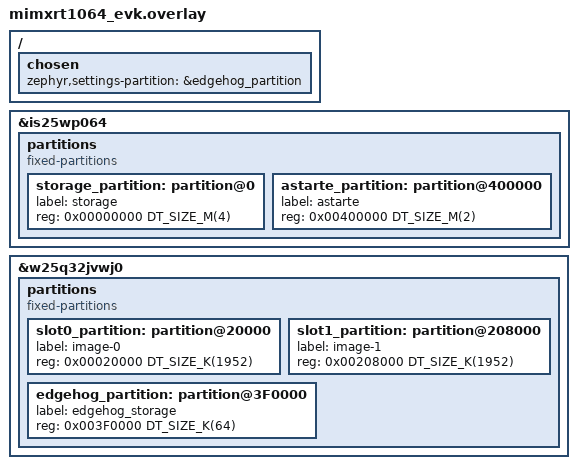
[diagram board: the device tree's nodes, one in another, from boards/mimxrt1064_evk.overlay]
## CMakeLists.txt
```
# (C) Copyright 2024, SECO Mind Srl
#
# SPDX-License-Identifier: Apache-2.0

function(concat_if_exists FILE_PATH STRING_NAME)
    # Check if the file exists
    file(GLOB FILE_TO_ADD ${FILE_PATH})

    # If the file exists, add it to the list
    if(EXISTS ${FILE_TO_ADD})
        set(${STRING_NAME} "${${STRING_NAME}};${FILE_PATH}" PARENT_SCOPE)
    endif()
endfunction()

cmake_minimum_required(VERSION 3.20.0)

# add private configuration for common modules before declaring the zephyr project
concat_if_exists(${CMAKE_CURRENT_LIST_DIR}/private.conf EXTRA_CONF_FILE)

find_package(Zephyr REQUIRED HINTS $ENV{ZEPHYR_BASE})
project(edgehog_app)

FILE(GLOB app_sources ${CMAKE_CURRENT_LIST_DIR}/src/*.c)
if(NOT CONFIG_WIFI)
    LIST(REMOVE_ITEM app_sources ${CMAKE_CURRENT_LIST_DIR}/src/wifi.c)
endif()
if(NOT CONFIG_EDGEHOG_DEVICE_FILE_TRANSFER)
    LIST(REMOVE_ITEM app_sources ${CMAKE_CURRENT_LIST_DIR}/src/file_transfer.c)
endif()

# Verify that this sample is built through sysbuild to ensure MCUboot is
# automatically included and that sample specific MCUboot configurations are
# used when building MCUboot.
test_sysbuild()

target_include_directories(app PRIVATE src/include)
target_sources(app PRIVATE ${app_sources})
```

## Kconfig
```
# (C) Copyright 2024, SECO Mind Srl
#
# SPDX-License-Identifier: Apache-2.0
#
# This file is the application Kconfig entry point. All application Kconfig
# options can be defined here or included via other application Kconfig files.
# You can browse these options using the west targets menuconfig (terminal) or
# guiconfig (GUI).

menu "Zephyr"
source "Kconfig.zephyr"
endmenu

rsource "../../Kconfig"

menu "Sample application"

config WIFI_SSID
    string "WiFi SSID"
	depends on WIFI
    default ""
	help
	  WiFi access point SSID.

config WIFI_PASSWORD
    string "WiFi password"
	depends on WIFI
    default ""
    help
        WiFi access point password.

config ASTARTE_DEVICE_ID
	string "Astarte device ID"
    default ""
	help
	  Device ID to be used to connect to Astarte.

config ASTARTE_CREDENTIAL_SECRET
    string "Astarte credential secret"
    default ""
    help
        The credential secret to be used to connect to Astarte.

config SAMPLE_DURATION_SECONDS
    int "Sample maximum duration (s)"
    default 240
    help
        Use this setting to change for how long the sample will run.
        The default is four minutes.

config EDGEHOG_DEVICE_THREAD_STACK_SIZE
    int "Edgehog device thread stack size (Bytes)"
    default 16384
    help
        Use this setting to change the size of the stack for the thread running the Astarte device.

config EDGEHOG_DEVICE_THREAD_PRIORITY
    int "Edgehog device thread priority"
    default 0
    help
        Use this setting to change the priority of the Astarte device thread.

config ZBUS_THREAD_STACK_SIZE
    int "Zbus thread stack size (Bytes)"
    default 16384
    help
        Use this setting to change the size of the stack for the thread running the Zbus subscriber.

config ZBUS_THREAD_PRIORITY
    int "Zbus thread priority"
    default 0
    help
        Use this setting to change the priority of the Zbus subscriber thread.

endmenu

module = APP
module-str = APP
source "subsys/logging/Kconfig.template.log_config"
```

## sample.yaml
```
# (C) Copyright 2024, SECO Mind Srl
#
# SPDX-License-Identifier: Apache-2.0
# This file is provided so that the application can be compiled using Twister,
# the Zephyr testing tool. In this file, multiple combinations can be specified,
# so that you can easily test all of them locally or in CI.
sample:
  description: Edgehog application sample
  name: edgehog-sample
tests:
  sample.default:
    build_only: true
    sysbuild: true
    integration_platforms:
      - mimxrt1064_evk
      - mimxrt1060_evk@B/mimxrt1062/qspi
      - stm32h573i_dk
      - esp_wrover_kit/esp32/procpu
  sample.wifi:
    build_only: true
    sysbuild: true
    extra_args: EXTRA_CONF_FILE="prj-wifi.conf"
    integration_platforms:
      - frdm_rw612
  sample.msv:
    build_only: true
    sysbuild: true
    extra_args: CONF_FILE="prj-zephyr-msv.conf"
    integration_platforms:
      - frdm_rw612
      - stm32h573i_dk
```

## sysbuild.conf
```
# (C) Copyright 2024, SECO Mind Srl
#
# SPDX-License-Identifier: Apache-2.0

SB_CONFIG_BOOTLOADER_MCUBOOT=y
SB_CONFIG_MCUBOOT_MODE_OVERWRITE_ONLY=y
```

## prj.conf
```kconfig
# (C) Copyright 2024, SECO Mind Srl
#
# SPDX-License-Identifier: Apache-2.0
#
# This is a Kconfig fragment which can be used to enable debug-related options
# in the application. See the README for more details.

# Astarte device SDK
CONFIG_ASTARTE_DEVICE_SDK=y
CONFIG_ASTARTE_DEVICE_SDK_HOSTNAME="."
# The two certificate tags are the same as the root CA is the same for Astarte API and MQTT broker.
CONFIG_ASTARTE_DEVICE_SDK_HTTPS_CA_CERT_TAG=1
CONFIG_ASTARTE_DEVICE_SDK_MQTTS_CA_CERT_TAG=1
CONFIG_ASTARTE_DEVICE_SDK_CLIENT_CERT_TAG=2
CONFIG_ASTARTE_DEVICE_SDK_PAIRING_JWT=""
CONFIG_ASTARTE_DEVICE_SDK_REALM_NAME="."

# Edgehog device
CONFIG_EDGEHOG_DEVICE=y
CONFIG_EDGEHOG_DEVICE_OTA_HTTPS_CA_CERT_TAG=3
CONFIG_EDGEHOG_DEVICE_ZBUS_OTA_EVENT=y
# System info interface data
CONFIG_EDGEHOG_DEVICE_PART_NUMBER=""
CONFIG_EDGEHOG_DEVICE_SERIAL_NUMBER=""

# Sample configuration
CONFIG_ASTARTE_CREDENTIAL_SECRET="."
CONFIG_ASTARTE_DEVICE_ID="......................"

# Enable logging with floating point support
CONFIG_LOG=y
CONFIG_REQUIRES_FLOAT_PRINTF=y
CONFIG_CBPRINTF_FP_SUPPORT=y

# Increase minimum heap size.
CONFIG_HEAP_MEM_POOL_SIZE=16384

# Increased stack size
CONFIG_MAIN_STACK_SIZE=8192

# Use custom heap
CONFIG_ASTARTE_DEVICE_SDK_ENABLE_HEAP=y

# Enable base64 encoding and decoding
CONFIG_BASE64=y

# Enable system hashmaps
CONFIG_SYS_HASH_MAP=y

# Enable JSON library
CONFIG_JSON_LIBRARY=y

# Enable entropy generator
CONFIG_ENTROPY_GENERATOR=y

# DNS resolver
CONFIG_DNS_RESOLVER=y
CONFIG_DNS_SERVER_IP_ADDRESSES=y
CONFIG_DNS_SERVER1="8.8.8.8" # Google DNS

# Base MbedTLS & heap configuration
CONFIG_MBEDTLS=y
CONFIG_MBEDTLS_BUILTIN=y
CONFIG_MBEDTLS_ENABLE_HEAP=y
CONFIG_MBEDTLS_HEAP_SIZE=95000

# Enable PSA Crypto Backend
CONFIG_PSA_CRYPTO=y
CONFIG_PSA_CRYPTO_ENABLE_ALL=y
CONFIG_MBEDTLS_PSA_CRYPTO_C=y

# TLS & X.509
CONFIG_MBEDTLS_SSL_MAX_CONTENT_LEN=8192
CONFIG_MBEDTLS_PEM_PARSE_C=y
CONFIG_MBEDTLS_PEM_WRITE_C=y
CONFIG_MBEDTLS_BASE64_C=y
CONFIG_MBEDTLS_PK_WRITE_C=y
CONFIG_MBEDTLS_SSL_PROTO_TLS1_2=y
CONFIG_MBEDTLS_SSL_SERVER_NAME_INDICATION=y
CONFIG_MBEDTLS_X509_USE_C=y
CONFIG_MBEDTLS_X509_CRT_PARSE_C=y
CONFIG_MBEDTLS_X509_CRL_PARSE_C=y
CONFIG_MBEDTLS_X509_CSR_PARSE_C=y
CONFIG_MBEDTLS_X509_CSR_WRITE_C=y
CONFIG_MBEDTLS_PKCS5_C=y
CONFIG_MBEDTLS_KEY_EXCHANGE_ECDHE_ECDSA_ENABLED=y
CONFIG_MBEDTLS_KEY_EXCHANGE_ECDHE_RSA_ENABLED=y

# Enable networking
CONFIG_NETWORKING=y

# Sockets
CONFIG_NET_SOCKETS=y
CONFIG_NET_SOCKETS_SOCKOPT_TLS=y

# Use DHCP for IPv4 and IPv6
CONFIG_NET_DHCPV4=y
CONFIG_NET_DHCPV6=y

# Generic networking options
CONFIG_NET_TX_STACK_SIZE=4096
CONFIG_NET_RX_STACK_SIZE=4096
CONFIG_NET_PKT_RX_COUNT=20
CONFIG_NET_PKT_TX_COUNT=20
CONFIG_NET_BUF_RX_COUNT=40
CONFIG_NET_BUF_TX_COUNT=40
CONFIG_NET_MAX_CONTEXTS=20
CONFIG_NET_MAX_CONN=6
CONFIG_NET_MGMT=y
CONFIG_NET_MGMT_EVENT=y
CONFIG_NET_IPV4=y
CONFIG_NET_IPV6=y
CONFIG_NET_TCP=y

# Enable HTTP client
CONFIG_HTTP_CLIENT=y

# MQTT options
CONFIG_MQTT_LIB=y
CONFIG_MQTT_LIB_TLS=y
CONFIG_MQTT_KEEPALIVE=60

# Enable flash
CONFIG_FLASH=y
CONFIG_FLASH_MAP=y
CONFIG_FLASH_PAGE_LAYOUT=y

# Enable NVS
CONFIG_NVS=y
CONFIG_NVS_LOG_LEVEL_WRN=y

# Enable storage
CONFIG_ZMS=y
CONFIG_ZMS_LOG_LEVEL_WRN=y

# Enable hash functions
CONFIG_SYS_HASH_FUNC32=y
CONFIG_SYS_HASH_FUNC32_MURMUR3=y


# Configure the name of the binary
# This will also be used to identify the edgehog image
CONFIG_KERNEL_BIN_NAME="sample-edgehog-app"

# Edgehog depends on
CONFIG_IMG_MANAGER=y
CONFIG_STREAM_FLASH=y
CONFIG_REBOOT=y

CONFIG_DNS_RESOLVER_AI_MAX_ENTRIES=4
CONFIG_NET_SOCKETS_TLS_MAX_CONTEXTS=4
CONFIG_TLS_MAX_CREDENTIALS_NUMBER=8

CONFIG_THREAD_MONITOR=y
CONFIG_INIT_STACKS=y
CONFIG_THREAD_STACK_INFO=y

CONFIG_ZVFS_OPEN_MAX=26

CONFIG_SNTP=y
CONFIG_NET_CONFIG_CLOCK_SNTP_INIT=y
CONFIG_NET_CONFIG_SNTP_INIT_SERVER="0.pool.ntp.org"
CONFIG_NET_CONFIG_SNTP_INIT_TIMEOUT=3000

# Enable the settings
CONFIG_SETTINGS=y

# Activate Zbus
CONFIG_ZBUS=y

# Activate thread naming
CONFIG_THREAD_NAME=y

# Enable events
CONFIG_EVENTS=y

# Enable littlefs
CONFIG_FILE_SYSTEM=y
CONFIG_FILE_SYSTEM_LITTLEFS=y

# Increase the system workqueue stack
CONFIG_SYSTEM_WORKQUEUE_STACK_SIZE=4096

# Enable UUID
CONFIG_UUID=y
CONFIG_UUID_V4=y
CONFIG_UUID_V5=y
CONFIG_UUID_BASE64=y

# Enable LZ4 compression
CONFIG_LZ4=y
CONFIG_LZ4_FRAME_SUPPORT=y

# Enable scoped cleanup helpers
CONFIG_SCOPE_CLEANUP_HELPERS=y
```

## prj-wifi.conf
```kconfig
# (C) Copyright 2025, SECO Mind Srl
#
# SPDX-License-Identifier: Apache-2.0
#
# This is a Kconfig fragment which can be used to enable debug-related options
# in the application. See the README for more details.

CONFIG_WIFI=y
CONFIG_ETH_DRIVER=n

CONFIG_NET_IPV6=n
CONFIG_NET_DHCPV6=n

# Increased stack size
CONFIG_MAIN_STACK_SIZE=65536
```

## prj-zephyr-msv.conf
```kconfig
# (C) Copyright 2026, SECO Mind Srl
#
# SPDX-License-Identifier: Apache-2.0
#
# This is a Kconfig fragment which can be used to enable debug-related options
# in the application. See the README for more details.

# Astarte device SDK
CONFIG_ASTARTE_DEVICE_SDK=y
CONFIG_ASTARTE_DEVICE_SDK_HOSTNAME="."
# The two certificate tags are the same as the root CA is the same for Astarte API and MQTT broker.
CONFIG_ASTARTE_DEVICE_SDK_HTTPS_CA_CERT_TAG=1
CONFIG_ASTARTE_DEVICE_SDK_MQTTS_CA_CERT_TAG=1
CONFIG_ASTARTE_DEVICE_SDK_CLIENT_CERT_TAG=2
CONFIG_ASTARTE_DEVICE_SDK_PAIRING_JWT=""
CONFIG_ASTARTE_DEVICE_SDK_REALM_NAME="."
# Edgehog device
CONFIG_EDGEHOG_DEVICE=y
CONFIG_EDGEHOG_DEVICE_OTA_HTTPS_CA_CERT_TAG=3
CONFIG_EDGEHOG_DEVICE_ZBUS_OTA_EVENT=y
# System info interface data
CONFIG_EDGEHOG_DEVICE_PART_NUMBER=""
CONFIG_EDGEHOG_DEVICE_SERIAL_NUMBER=""

# Sample configuration
CONFIG_ASTARTE_CREDENTIAL_SECRET="."
CONFIG_ASTARTE_DEVICE_ID="......................"

# Enable logging with floating point support
CONFIG_LOG=y
CONFIG_REQUIRES_FLOAT_PRINTF=y
CONFIG_CBPRINTF_FP_SUPPORT=y

# Increase minimum heap size.
CONFIG_HEAP_MEM_POOL_SIZE=16384

# Increased stack size
CONFIG_MAIN_STACK_SIZE=8192

# Use custom heap
CONFIG_ASTARTE_DEVICE_SDK_ENABLE_HEAP=y

# Enable base64 encoding and decoding
CONFIG_BASE64=y

# Enable system hashmaps
CONFIG_SYS_HASH_MAP=y

# Enable JSON library
CONFIG_JSON_LIBRARY=y

# Enable entropy generator
CONFIG_ENTROPY_GENERATOR=y

# DNS resolver
CONFIG_DNS_RESOLVER=y
CONFIG_DNS_SERVER_IP_ADDRESSES=y
CONFIG_DNS_SERVER1="8.8.8.8" # Google DNS

# Base MbedTLS & heap configuration
CONFIG_MBEDTLS=y
CONFIG_MBEDTLS_BUILTIN=y
CONFIG_MBEDTLS_ENABLE_HEAP=y
CONFIG_MBEDTLS_HEAP_SIZE=55000

# Enable PSA Crypto Backend
CONFIG_PSA_CRYPTO=y
CONFIG_PSA_CRYPTO_ENABLE_ALL=y
CONFIG_MBEDTLS_USE_PSA_CRYPTO=y
CONFIG_MBEDTLS_PSA_CRYPTO_C=y

# TLS & X.509
CONFIG_MBEDTLS_SSL_MAX_CONTENT_LEN=8192
CONFIG_MBEDTLS_PEM_CERTIFICATE_FORMAT=y
CONFIG_MBEDTLS_PK_WRITE_C=y
CONFIG_MBEDTLS_SSL_PROTO_TLS1_2=y
CONFIG_MBEDTLS_SERVER_NAME_INDICATION=y
CONFIG_MBEDTLS_X509_CRL_PARSE_C=y
CONFIG_MBEDTLS_X509_CSR_PARSE_C=y
CONFIG_MBEDTLS_X509_CSR_WRITE_C=y
CONFIG_MBEDTLS_PKCS5_C=y
CONFIG_MBEDTLS_GENPRIME_ENABLED=y
CONFIG_MBEDTLS_KEY_EXCHANGE_ECDHE_ECDSA_ENABLED=y
CONFIG_MBEDTLS_KEY_EXCHANGE_ECDHE_RSA_ENABLED=y
CONFIG_MBEDTLS_ECDH_C=y
CONFIG_MBEDTLS_ECDSA_C=y
CONFIG_MBEDTLS_ECP_C=y
CONFIG_MBEDTLS_ECP_DP_SECP256R1_ENABLED=y

# Enable networking
CONFIG_NETWORKING=y

# Sockets
CONFIG_NET_SOCKETS=y
CONFIG_NET_SOCKETS_SOCKOPT_TLS=y

# Use DHCP for IPv4 and IPv6
CONFIG_NET_DHCPV4=y
CONFIG_NET_DHCPV6=y

# Generic networking options
CONFIG_NET_TX_STACK_SIZE=4096
CONFIG_NET_RX_STACK_SIZE=4096
CONFIG_NET_PKT_RX_COUNT=20
CONFIG_NET_PKT_TX_COUNT=20
CONFIG_NET_BUF_RX_COUNT=40
CONFIG_NET_BUF_TX_COUNT=40
CONFIG_NET_MAX_CONTEXTS=20
CONFIG_NET_MAX_CONN=6
CONFIG_NET_MGMT=y
CONFIG_NET_MGMT_EVENT=y
CONFIG_NET_IPV4=y
CONFIG_NET_IPV6=y
CONFIG_NET_TCP=y

# Enable HTTP client
CONFIG_HTTP_CLIENT=y

# MQTT options
CONFIG_MQTT_LIB=y
CONFIG_MQTT_LIB_TLS=y
CONFIG_MQTT_KEEPALIVE=60

# Enable flash
CONFIG_FLASH=y
CONFIG_FLASH_MAP=y
CONFIG_FLASH_PAGE_LAYOUT=y

# Enable NVS
CONFIG_NVS=y
CONFIG_NVS_LOG_LEVEL_WRN=y

# Enable storage
CONFIG_ZMS=y
CONFIG_ZMS_LOG_LEVEL_WRN=y

# Enable hash functions
CONFIG_SYS_HASH_FUNC32=y
CONFIG_SYS_HASH_FUNC32_MURMUR3=y

# Configure the name of the binary
# This will also be used to identify the edgehog image
CONFIG_KERNEL_BIN_NAME="sample-edgehog-app"

# Edgehog depends on
CONFIG_IMG_MANAGER=y
CONFIG_STREAM_FLASH=y
CONFIG_REBOOT=y

CONFIG_DNS_RESOLVER_AI_MAX_ENTRIES=4
CONFIG_NET_SOCKETS_TLS_MAX_CONTEXTS=4
CONFIG_TLS_MAX_CREDENTIALS_NUMBER=8

CONFIG_THREAD_MONITOR=y
CONFIG_INIT_STACKS=y
CONFIG_THREAD_STACK_INFO=y

CONFIG_ZVFS_OPEN_MAX=26

CONFIG_SNTP=y
CONFIG_NET_CONFIG_CLOCK_SNTP_INIT=y
CONFIG_NET_CONFIG_SNTP_INIT_SERVER="0.pool.ntp.org"
CONFIG_NET_CONFIG_SNTP_INIT_TIMEOUT=3000

# Enable the settings
CONFIG_SETTINGS=y

# Activate Zbus
CONFIG_ZBUS=y

# Set thread names
CONFIG_THREAD_NAME=y

# Enable UUID
CONFIG_UUID=y
CONFIG_UUID_V4=y
CONFIG_UUID_V5=y
CONFIG_UUID_BASE64=y

# Enable events
CONFIG_EVENTS=y
```

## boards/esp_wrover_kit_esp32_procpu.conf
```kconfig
# (C) Copyright 2026, SECO Mind Srl
#
# SPDX-License-Identifier: Apache-2.0

# Wi-Fi Configuration
CONFIG_WIFI=y
CONFIG_WIFI_ESP32=y

# increase network buffer size to avoid first connection attempt error
CONFIG_NET_BUF_TX_COUNT=64
CONFIG_NET_BUF_RX_COUNT=64

# ESP32 hardware random number generator is required for secure TLS
CONFIG_ENTROPY_ESP32_RNG=y

# Enable WROVER PSRAM
CONFIG_ESP_SPIRAM=y
# 2MB instead of deafult 256KB
CONFIG_ESP_SPIRAM_HEAP_SIZE=2097152

# Optimizations to save internal RAM used by the Wi-Fi driver
CONFIG_ESP_WIFI_HEAP_SPIRAM=y
CONFIG_ESP32_WIFI_NET_ALLOC_SPIRAM=y
CONFIG_ESP32_WIFI_RX_IRAM_OPT=n
CONFIG_ESP32_WIFI_IRAM_OPT=n

# Move MbedTLS heap to external RAM
CONFIG_MBEDTLS_HEAP_CUSTOM_SECTION=y
```

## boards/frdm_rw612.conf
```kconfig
# (C) Copyright 2025, SECO Mind Srl
#
# SPDX-License-Identifier: Apache-2.0

# Enable the WiFi
CONFIG_WIFI_NXP=y

# Use a large log buffer size
CONFIG_LOG_BUFFER_SIZE=32768

# Enable the file transfer
CONFIG_EDGEHOG_DEVICE_FILE_TRANSFER=y
CONFIG_EDGEHOG_DEVICE_FILE_TRANSFER_HTTPS_CA_CERT_TAG=4
CONFIG_EDGEHOG_DEVICE_FILE_TRANSFER_COMPRESSION=y
CONFIG_EDGEHOG_DEVICE_FILE_TRANSFER_TAR=y
```

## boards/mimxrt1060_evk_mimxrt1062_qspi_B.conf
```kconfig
# (C) Copyright 2024, SECO Mind Srl
#
# SPDX-License-Identifier: Apache-2.0

# Ethernet settings
CONFIG_NET_L2_ETHERNET=y
CONFIG_NET_L2_ETHERNET_MGMT=y

CONFIG_LOG_MODE_DEFERRED=y
CONFIG_LOG_BUFFER_SIZE=32768
```

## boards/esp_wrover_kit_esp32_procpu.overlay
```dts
/*
 * (C) Copyright 2026, SECO Mind Srl
 *
 * SPDX-License-Identifier: Apache-2.0
 */

/delete-node/ &storage_partition;

&flash0 {
	partitions {
		compatible = "fixed-partitions";
		#address-cells = <1>;
		#size-cells = <1>;

        storage_partition: partition@3b0000 {
			label = "storage";
			reg = <0x3B0000 DT_SIZE_K(64)>;
		};

		astarte_partition: partition@3c0000 {
			label = "astarte";
			reg = <0x003C0000 DT_SIZE_K(64)>;
		};

		edgehog_partition: partition@3d0000 {
			label = "edgehog";
			reg = <0x003D0000 DT_SIZE_K(64)>;
		};
	};
};
```

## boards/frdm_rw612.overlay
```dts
/*
 * (C) Copyright 2025, SECO Mind Srl
 *
 * SPDX-License-Identifier: Apache-2.0
 */

/delete-node/ &storage_partition;

/ {
    fstab {
        compatible = "zephyr,fstab";
        lfs1: lfs1 {
            compatible = "zephyr,fstab,littlefs";
            mount-point = "/lfs1";
            partition = <&file_transfer_partition>;
            automount;
            read-size = <16>;
            prog-size = <16>;
            cache-size = <64>;
            lookahead-size = <32>;
            block-cycles = <512>;
        };
    };
};

&w25q512jvfiq {
    partitions {
        compatible = "fixed-partitions";
        #address-cells = <1>;
        #size-cells = <1>;

        storage_partition: partition@620000 {
            label = "storage";
            reg = <0x00620000 (DT_SIZE_M(55) - DT_SIZE_K(128))>;
        };

        astarte_partition: partition@3D00000 {
            label = "astarte";
            reg = <0x03D00000 DT_SIZE_M(1)>;
        };

        edgehog_partition: partition@3E00000 {
            label = "edgehog";
            reg = <0x03E00000 DT_SIZE_M(1)>;
        };

        file_transfer_partition: partition@3F00000 {
            label = "file_transfer";
            reg = <0x03F00000 DT_SIZE_M(1)>;
        };
    };
};

/ {
    chosen {
        zephyr,settings-partition = &edgehog_partition;
    };
};
```

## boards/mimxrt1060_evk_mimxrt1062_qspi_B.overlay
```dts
/*
 * (C) Copyright 2024, SECO Mind Srl
 *
 * SPDX-License-Identifier: Apache-2.0
 */

/delete-node/ &storage_partition;

/delete-node/ &slot0_partition;
/delete-node/ &slot1_partition;

&is25wp064 {
    partitions {
        compatible = "fixed-partitions";
        #address-cells = <1>;
        #size-cells = <1>;

        slot0_partition: partition@20000 {
            label = "image-0";
            reg = <0x00020000 DT_SIZE_K(1952)>;
        };

        slot1_partition: partition@208000 {
            label = "image-1";
            reg = <0x00208000 DT_SIZE_K(1952)>;
        };

        storage_partition: partition@3F0000 {
            label = "storage";
            reg = <0x003F0000 DT_SIZE_M(1)>;
        };

        astarte_partition: partition@4F0000 {
            label = "astarte";
            reg = <0x004F0000 DT_SIZE_M(1)>;
        };

        edgehog_partition: partition@5F0000 {
            label = "edgehog_storage";
            reg = <0x005F0000 DT_SIZE_K(64)>;
        };
    };
};

/ {
    chosen {
        zephyr,settings-partition = &edgehog_partition;
    };
};
```

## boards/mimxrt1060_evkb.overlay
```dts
/*
 * (C) Copyright 2024, SECO Mind Srl
 *
 * SPDX-License-Identifier: Apache-2.0
 */

/delete-node/ &storage_partition;

/delete-node/ &slot0_partition;
/delete-node/ &slot1_partition;

&is25wp064 {
	partitions {
		compatible = "fixed-partitions";
		#address-cells = <1>;
		#size-cells = <1>;

		slot0_partition: partition@20000 {
			label = "image-0";
			reg = <0x00020000 DT_SIZE_K(1952)>;
		};

		slot1_partition: partition@208000 {
			label = "image-1";
			reg = <0x00208000 DT_SIZE_K(1952)>;
		};

		storage_partition: partition@3F0000 {
			label = "storage";
			reg = <0x003F0000 DT_SIZE_M(1)>;
		};

		astarte_partition: partition@4F0000 {
			label = "astarte";
			reg = <0x004F0000 DT_SIZE_M(1)>;
		};

		edgehog_partition: partition@5F0000 {
			label = "edgehog_storage";
			reg = <0x005F0000 DT_SIZE_K(64)>;
		};
	};
};

/ {
	chosen {
		zephyr,settings-partition = &edgehog_partition;
	};
};
```

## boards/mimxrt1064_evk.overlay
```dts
/*
 * (C) Copyright 2024, SECO Mind Srl
 *
 * SPDX-License-Identifier: Apache-2.0
 */

/delete-node/ &storage_partition;

/delete-node/ &slot0_partition;
/delete-node/ &slot1_partition;

&is25wp064 {
    partitions {
        compatible = "fixed-partitions";
        #address-cells = <1>;
        #size-cells = <1>;

        storage_partition: partition@0 {
            label = "storage";
            reg = <0x00000000 DT_SIZE_M(4)>;
        };

        astarte_partition: partition@400000 {
            label = "astarte";
            reg = <0x00400000 DT_SIZE_M(2)>;
        };
    };
};


&w25q32jvwj0 {
    partitions {
        compatible = "fixed-partitions";
        #address-cells = <1>;
        #size-cells = <1>;

        slot0_partition: partition@20000 {
            label = "image-0";
            reg = <0x00020000 DT_SIZE_K(1952)>;
        };

        slot1_partition: partition@208000 {
            label = "image-1";
            reg = <0x00208000 DT_SIZE_K(1952)>;
        };

        /*
        * Reserve the final 64 KiB for edgehog partition
        */
        edgehog_partition: partition@3F0000 {
            label = "edgehog_storage";
            reg = <0x003F0000 DT_SIZE_K(64)>;
        };
    };
};

/ {
    chosen {
        zephyr,settings-partition = &edgehog_partition;
    };
};
```

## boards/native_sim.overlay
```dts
/*
 * (C) Copyright 2024, SECO Mind Srl
 *
 * SPDX-License-Identifier: Apache-2.0
 */

&flash0 {
    partitions {
        compatible = "fixed-partitions";
        #address-cells = <1>;
        #size-cells = <1>;

        astarte_partition: partition@100000 {
            label = "astarte";
            reg = <0x00100000 DT_SIZE_K(128)>;
        };
        edgehog_partition: partition@120000 {
            label = "edgehog";
            reg = <0x00120000 DT_SIZE_K(128)>;
        };
    };
};

/ {
    chosen {
        zephyr,settings-partition = &edgehog_partition;
    };
};
```

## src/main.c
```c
/*
 * (C) Copyright 2024, SECO Mind Srl
 *
 * SPDX-License-Identifier: Apache-2.0
 */

#include <time.h>

#include <zephyr/kernel.h>
#include <zephyr/net/net_mgmt.h>
#include <zephyr/net/sntp.h>
#include <zephyr/sys/clock.h>

#include <zephyr/logging/log.h>
LOG_MODULE_REGISTER(edgehog_app, CONFIG_APP_LOG_LEVEL); // NOLINT

#if (!defined(CONFIG_ASTARTE_DEVICE_SDK_DEVELOP_USE_NON_TLS_HTTP)                                  \
    || !defined(CONFIG_ASTARTE_DEVICE_SDK_DEVELOP_USE_NON_TLS_MQTT))
#include "ca_certificates.h"
#include <zephyr/net/tls_credentials.h>
#endif

#include <astarte_device_sdk/device.h>

#ifdef CONFIG_EDGEHOG_DEVICE_ZBUS_OTA_EVENT
#include <edgehog_device/ota_event.h>
#endif
#include <edgehog_device/device.h>
#include <edgehog_device/telemetry.h>

#ifdef CONFIG_WIFI
#include "wifi.h"
#else
#include "eth.h"
#endif

#ifdef CONFIG_EDGEHOG_DEVICE_FILE_TRANSFER
#include "file_transfer.h"
#endif

/************************************************
 *             Constants and defines            *
 ***********************************************/

#define MAIN_THREAD_PERIOD_MS 500
#define EDGEHOG_DEVICE_PERIOD_MS 500
#ifdef CONFIG_EDGEHOG_DEVICE_ZBUS_OTA_EVENT
#define ZBUS_PERIOD_MS 500
#endif

#define HTTP_TIMEOUT_MS (3 * MSEC_PER_SEC)
#define MQTT_FIRST_POLL_TIMEOUT_MS (3 * MSEC_PER_SEC)
#define MQTT_POLL_TIMEOUT_MS 200

#define TELEMETRY_SYSTEM_STATUS_PERIOD_S 5
#define TELEMETRY_WIFI_SCAN_PERIOD_S 30

// NOLINTBEGIN(cppcoreguidelines-avoid-non-const-global-variables)
enum device_tread_flags
{
    DEVICE_THREADS_FLAGS_TERMINATION = 1U,
    DEVICE_THREADS_FLAGS_CONNECT_ASTARTE,
    DEVICE_THREADS_FLAGS_START_EDGEHOG,
};
static atomic_t device_threads_flags;

K_THREAD_STACK_DEFINE(edgehog_device_thread_stack_area, CONFIG_EDGEHOG_DEVICE_THREAD_STACK_SIZE);
static struct k_thread edgehog_device_thread_data;

static edgehog_device_handle_t edgehog_device;

#ifdef CONFIG_EDGEHOG_DEVICE_ZBUS_OTA_EVENT
K_THREAD_STACK_DEFINE(zbus_thread_stack_area, CONFIG_ZBUS_THREAD_STACK_SIZE);
static struct k_thread zbus_thread_data;
// Define a zbus subscriber and add it as an observer to the Edgehog OTA channel
#define EDGEHOG_OTA_SUBSCRIBER_NOTIFICATION_QUEUE_SIZE 5
#define EDGEHOG_OTA_OBSERVER_NOTIFY_PRIORITY 5
ZBUS_SUBSCRIBER_DEFINE(edgehog_ota_subscriber, EDGEHOG_OTA_SUBSCRIBER_NOTIFICATION_QUEUE_SIZE);
ZBUS_CHAN_ADD_OBS(edgehog_ota_chan, edgehog_ota_subscriber, EDGEHOG_OTA_OBSERVER_NOTIFY_PRIORITY);
#endif
// NOLINTEND(cppcoreguidelines-avoid-non-const-global-variables)

/************************************************
 *         Static functions declarations        *
 ***********************************************/

/**
 * @brief Initialize System Time
 */
static void system_time_init(void);
/**
 * @brief Entry point for the Edgehog device thread.
 *
 * @param arg1 Unused argument.
 * @param arg2 Unused argument.
 * @param arg3 Unused argument.
 */
static void edgehog_device_thread_entry_point(void *arg1, void *arg2, void *arg3);
#ifdef CONFIG_EDGEHOG_DEVICE_ZBUS_OTA_EVENT
/**
 * @brief Entry point for the Zbus reception thread.
 *
 * @param arg1 Unused argument.
 * @param arg2 Unused argument.
 * @param arg3 Unused argument.
 */
static void zbus_thread_entry_point(void *arg1, void *arg2, void *arg3);
/**
 * @brief Listen on the Edgehog zbus channel for events.
 *
 * @param timeout The timeout used for listening. In case of a received notification this timeout
 * is also used for reading the message.
 */
static void edgehog_listen_zbus_channel(k_timeout_t timeout);
#endif

/************************************************
 *         Global functions definition          *
 ***********************************************/

// NOLINTNEXTLINE(hicpp-function-size)
int main(void)
{
    LOG_INF("Edgehog device sample"); // NOLINT
    LOG_INF("Board: %s", CONFIG_BOARD); // NOLINT

#ifdef CONFIG_WIFI
    LOG_INF("Initializing WiFi driver."); // NOLINT
    app_wifi_init();
    k_sleep(K_SECONDS(5));
    const char *ssid = CONFIG_WIFI_SSID;
    enum wifi_security_type sec = WIFI_SECURITY_TYPE_PSK;
    const char *psk = CONFIG_WIFI_PASSWORD;
    if (app_wifi_connect(ssid, sec, psk) != 0) {
        LOG_ERR("Connectivity intialization failed!"); // NOLINT
        return -1;
    }
#else
    LOG_INF("Initializing Ethernet driver."); // NOLINT
    if (eth_connect() != 0) {
        LOG_ERR("Connectivity intialization failed!"); // NOLINT
        return -1;
    }
#endif

    // Add TLS certificate for Astarte if required
#if (!defined(CONFIG_ASTARTE_DEVICE_SDK_DEVELOP_USE_NON_TLS_HTTP)                                  \
    || !defined(CONFIG_ASTARTE_DEVICE_SDK_DEVELOP_USE_NON_TLS_MQTT))
    tls_credential_add(CONFIG_ASTARTE_DEVICE_SDK_HTTPS_CA_CERT_TAG, TLS_CREDENTIAL_CA_CERTIFICATE,
        astarte_ca_certificate_root, sizeof(astarte_ca_certificate_root));
#endif

    // Add TLS certificate for Edgehog if required
#ifndef CONFIG_EDGEHOG_DEVICE_DEVELOP_USE_NON_TLS_HTTP
    tls_credential_add(CONFIG_EDGEHOG_DEVICE_OTA_HTTPS_CA_CERT_TAG, TLS_CREDENTIAL_CA_CERTIFICATE,
        edgehog_ota_ca_certificate_root, sizeof(edgehog_ota_ca_certificate_root));
#ifdef CONFIG_EDGEHOG_DEVICE_FILE_TRANSFER_HTTPS_CA_CERT_TAG
    tls_credential_add(CONFIG_EDGEHOG_DEVICE_FILE_TRANSFER_HTTPS_CA_CERT_TAG,
        TLS_CREDENTIAL_CA_CERTIFICATE, edgehog_ft_ca_certificate_root,
        sizeof(edgehog_ft_ca_certificate_root));
#endif
#endif

    // Initialize system time
    system_time_init();

    // Spawn a new thread for the Edgehog device
    k_tid_t thread_id = k_thread_create(&edgehog_device_thread_data,
        edgehog_device_thread_stack_area, K_THREAD_STACK_SIZEOF(edgehog_device_thread_stack_area),
        edgehog_device_thread_entry_point, NULL, NULL, NULL, CONFIG_EDGEHOG_DEVICE_THREAD_PRIORITY,
        0, K_NO_WAIT);

#ifdef CONFIG_THREAD_NAME
    int ret = k_thread_name_set(thread_id, "sample_edgehog_device_thread");
    if (ret != 0) {
        LOG_ERR("Failed to set thread name, error %d", ret); // NOLINT
    }
#endif

    // Wait for a predefined operational time.
    k_timepoint_t finish_timepoint = sys_timepoint_calc(K_SECONDS(CONFIG_SAMPLE_DURATION_SECONDS));
    while (!K_TIMEOUT_EQ(sys_timepoint_timeout(finish_timepoint), K_NO_WAIT)) {
        k_timepoint_t timepoint = sys_timepoint_calc(K_MSEC(MAIN_THREAD_PERIOD_MS));
#ifndef CONFIG_WIFI
        if (eth_poll() != 0) {
            LOG_ERR("Failed polling Ethernet."); // NOLINT
        }
#endif
        k_sleep(sys_timepoint_timeout(timepoint));
    }

    // Signal to the Device threads that they should terminate.
    atomic_set_bit(&device_threads_flags, DEVICE_THREADS_FLAGS_TERMINATION);

    // Wait for the Edgehog thread to terminate.
    if (k_thread_join(&edgehog_device_thread_data, K_FOREVER) != 0) {
        LOG_ERR("Failed in waiting for the Edgehog thread to terminate."); // NOLINT
    }

    LOG_INF("Edgehog device sample finished."); // NOLINT
    k_sleep(K_MSEC(MSEC_PER_SEC));

    return 0;
}

/************************************************
 * Static functions definitions
 ***********************************************/

static void system_time_init(void)
{
#ifdef CONFIG_SNTP
    int ret = 0;
    struct sntp_time now;
    struct timespec tspec;

    ret = sntp_simple(
        CONFIG_NET_CONFIG_SNTP_INIT_SERVER, CONFIG_NET_CONFIG_SNTP_INIT_TIMEOUT, &now);
    if (ret == 0) {
        tspec.tv_sec = (time_t) now.seconds;
        // NOLINTBEGIN(bugprone-narrowing-conversions, hicpp-signed-bitwise,
        // readability-magic-numbers)
        tspec.tv_nsec = ((uint64_t) now.fraction * (1000lu * 1000lu * 1000lu)) >> 32;
        // NOLINTEND(bugprone-narrowing-conversions, hicpp-signed-bitwise,
        // readability-magic-numbers)
        sys_clock_settime(CLOCK_REALTIME, &tspec);
    }
#endif
}

static void edgehog_device_thread_entry_point(void *arg1, void *arg2, void *arg3)
{
    ARG_UNUSED(arg1);
    ARG_UNUSED(arg2);
    ARG_UNUSED(arg3);

    // Configuring the Astarte device used by the Edgehog device to communicate with the cloud
    // Edgehog instance. This device can also be leveraged by the user to send and receive data
    // through Astarte, check out the sample README for more information.
    char cred_secr[ASTARTE_PAIRING_CRED_SECR_LEN + 1] = CONFIG_ASTARTE_CREDENTIAL_SECRET;
    char device_id[ASTARTE_DEVICE_ID_LEN + 1] = CONFIG_ASTARTE_DEVICE_ID;

    astarte_device_config_t astarte_device_config = { 0 };
    astarte_device_config.http_timeout_ms = HTTP_TIMEOUT_MS;
    astarte_device_config.mqtt_connection_timeout_ms = MQTT_FIRST_POLL_TIMEOUT_MS;
    astarte_device_config.mqtt_poll_timeout_ms = MQTT_POLL_TIMEOUT_MS;
    memcpy(astarte_device_config.cred_secr, cred_secr, sizeof(cred_secr));
    memcpy(astarte_device_config.device_id, device_id, sizeof(device_id));

    edgehog_result_t eres = EDGEHOG_RESULT_OK;

#ifdef CONFIG_EDGEHOG_DEVICE_FILE_TRANSFER
    edgehog_ft_filesystem_partition_t ft_partitions[]
        = { { .mount_point = "/lfs1", .permissions = EDGEHOG_FT_FILESYSTEM_PERM_RW } };

    // Register /lfs1 as a user storage partition for storage-usage telemetry
    edgehog_storage_partition_t storage_partitions[]
        = { { .type = EDGEHOG_STORAGE_PARTITION_TYPE_FS, .path = "/lfs1" } };
#endif

    edgehog_telemetry_config_t telemetry_config[]
        = { {
                .type = EDGEHOG_TELEMETRY_SYSTEM_STATUS,
                .period_seconds = TELEMETRY_SYSTEM_STATUS_PERIOD_S,
            },
              {
                  .type = EDGEHOG_TELEMETRY_WIFI_SCAN,
                  .period_seconds = TELEMETRY_WIFI_SCAN_PERIOD_S,
              } };

    edgehog_device_config_t edgehog_conf = { .astarte_device_config = astarte_device_config,
        .telemetry_config = telemetry_config,
        .telemetry_config_len = ARRAY_SIZE(telemetry_config),
#ifdef CONFIG_EDGEHOG_DEVICE_FILE_TRANSFER
        .file_transfer_cbks = { .on_stream_transfer_start = app_on_stream_transfer_start,
            .on_filesystem_transfer_done = app_on_filesystem_transfer_done },
        .file_transfer_partitions = ft_partitions,
        .file_transfer_partitions_len = ARRAY_SIZE(ft_partitions),
        .storage_partitions = storage_partitions,
        .storage_partitions_len = ARRAY_SIZE(storage_partitions)
#endif
    };

    eres = edgehog_device_new(&edgehog_conf, &edgehog_device);
    if (eres != EDGEHOG_RESULT_OK) {
        LOG_ERR("Unable to create edgehog device handle"); // NOLINT
        goto exit;
    }

    eres = edgehog_device_start(edgehog_device);
    if (eres != EDGEHOG_RESULT_OK) {
        LOG_ERR("Unable to start edgehog device"); // NOLINT
        goto exit;
    }

#ifdef CONFIG_EDGEHOG_DEVICE_ZBUS_OTA_EVENT
    // Spawn a new thread for listening on Zbus device
    k_tid_t thread_id = k_thread_create(&zbus_thread_data, zbus_thread_stack_area,
        K_THREAD_STACK_SIZEOF(zbus_thread_stack_area), zbus_thread_entry_point, NULL, NULL, NULL,
        CONFIG_ZBUS_THREAD_PRIORITY, 0, K_NO_WAIT);

#ifdef CONFIG_THREAD_NAME
    int ret = k_thread_name_set(thread_id, "sample_zbus_ota_thread");
    if (ret != 0) {
        LOG_ERR("Failed to set thread name, error %d", ret); // NOLINT
    }
#endif
#endif

    // Device management and communication are handled asynchronously by internal threads.
    // Loop until a termination signal is set.
    while (!atomic_test_bit(&device_threads_flags, DEVICE_THREADS_FLAGS_TERMINATION)) {
        k_msleep(EDGEHOG_DEVICE_PERIOD_MS);
    }

    LOG_INF("End of sample, stopping Edgehog."); // NOLINT
    eres = edgehog_device_stop(edgehog_device, K_FOREVER);
    if (eres != EDGEHOG_RESULT_OK) {
        LOG_ERR("Unable to stop the edgehog device"); // NOLINT
        goto exit;
    }

    LOG_INF("Edgehog device will now be destroyed."); // NOLINT
    edgehog_device_destroy(edgehog_device);

exit:
    // Ensure to set the thread termination flag
    atomic_set_bit(&device_threads_flags, DEVICE_THREADS_FLAGS_TERMINATION);

#ifdef CONFIG_EDGEHOG_DEVICE_ZBUS_OTA_EVENT
    // Wait for the Zbus thread to terminate.
    if (k_thread_join(&zbus_thread_data, K_SECONDS(10)) != 0) {
        LOG_ERR("Failed in waiting for the Zbus thread to terminate."); // NOLINT
    }
#endif
}

#ifdef CONFIG_EDGEHOG_DEVICE_ZBUS_OTA_EVENT
static void zbus_thread_entry_point(void *arg1, void *arg2, void *arg3)
{
    ARG_UNUSED(arg1);
    ARG_UNUSED(arg2);
    ARG_UNUSED(arg3);

    while (!atomic_test_bit(&device_threads_flags, DEVICE_THREADS_FLAGS_TERMINATION)) {
        edgehog_listen_zbus_channel(K_MSEC(ZBUS_PERIOD_MS));
    }
}

static void edgehog_listen_zbus_channel(k_timeout_t timeout)
{
    const struct zbus_channel *chan = NULL;
    edgehog_ota_chan_event_t ota = { 0 };
    if ((zbus_sub_wait(&edgehog_ota_subscriber, &chan, timeout) == 0) && (&edgehog_ota_chan == chan)
        && (zbus_chan_read(chan, &ota, timeout) == 0)) {
        switch (ota.event) {
            case EDGEHOG_OTA_INIT_EVENT:
                LOG_WRN("To subscriber -> EDGEHOG_OTA_INIT_EVENT"); // NOLINT
                break;
            case EDGEHOG_OTA_PENDING_REBOOT_EVENT:
                LOG_WRN("To subscriber -> EDGEHOG_OTA_PENDING_REBOOT_EVENT"); // NOLINT
                edgehog_ota_chan_event_t ota_chan_event
                    = { .event = EDGEHOG_OTA_CONFIRM_REBOOT_EVENT };
                zbus_chan_pub(&edgehog_ota_chan, &ota_chan_event, K_SECONDS(1));
                break;
            case EDGEHOG_OTA_CONFIRM_REBOOT_EVENT:
                LOG_WRN("To subscriber -> EDGEHOG_OTA_CONFIRM_REBOOT_EVENT"); // NOLINT
                break;
            case EDGEHOG_OTA_FAILED_EVENT:
                LOG_WRN("To subscriber -> EDGEHOG_OTA_FAILED_EVENT"); // NOLINT
                break;
            case EDGEHOG_OTA_SUCCESS_EVENT:
                LOG_WRN("To subscriber -> EDGEHOG_OTA_SUCCESS_EVENT"); // NOLINT
                break;
            default:
                LOG_WRN("To subscriber -> EDGEHOG_OTA_INVALID_EVENT"); // NOLINT
        }
    }
}
#endif
```

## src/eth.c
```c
/*
 * (C) Copyright 2024, SECO Mind Srl
 *
 * SPDX-License-Identifier: Apache-2.0
 */

#include "eth.h"

#include <zephyr/kernel.h>
#include <zephyr/net/ethernet.h>
#include <zephyr/net/ethernet_mgmt.h>
#include <zephyr/sys/atomic.h>
#include <zephyr/version.h>

#include <zephyr/logging/log.h>
LOG_MODULE_REGISTER(eth, CONFIG_APP_LOG_LEVEL); // NOLINT

/************************************************
 *        Constants, statics and defines        *
 ***********************************************/

// NOLINTBEGIN(cppcoreguidelines-avoid-non-const-global-variables)
static struct net_mgmt_event_callback eth_cb;
static struct net_mgmt_event_callback status_cb;
static struct net_mgmt_event_callback ipv6_cb;
static struct net_mgmt_event_callback ipv4_cb;
static struct net_mgmt_event_callback l4_cb;

enum eth_flags
{
    IPV4_ADDRESS_OBTAINED = 1U,
    IFACE_UP,
};
static atomic_t eth_flags;
// NOLINTEND(cppcoreguidelines-avoid-non-const-global-variables)

/************************************************
 *       Callbacks declaration/definition       *
 ***********************************************/

static void eth_mgmt_event_handler(
    struct net_mgmt_event_callback *event_cb, uint64_t mgmt_event, struct net_if *iface)
{
    (void) event_cb;
    (void) iface;

    // NOLINTBEGIN(hicpp-signed-bitwise)
    switch (mgmt_event) {
        case NET_EVENT_ETHERNET_CARRIER_ON:
            LOG_DBG("Ethernet event: NET_EVENT_ETHERNET_CARRIER_ON."); // NOLINT
            break;

        case NET_EVENT_ETHERNET_CARRIER_OFF:
            LOG_DBG("Ethernet event: NET_EVENT_ETHERNET_CARRIER_OFF."); // NOLINT
            break;

        case NET_EVENT_ETHERNET_VLAN_TAG_ENABLED:
            LOG_DBG("Ethernet event: NET_EVENT_ETHERNET_VLAN_TAG_ENABLED."); // NOLINT
            break;

        case NET_EVENT_ETHERNET_VLAN_TAG_DISABLED:
            LOG_DBG("Ethernet event: NET_EVENT_ETHERNET_VLAN_TAG_DISABLED."); // NOLINT
            break;

        default:
            LOG_DBG("Status network event: %lld.", mgmt_event); // NOLINT
            break;
    }
    // NOLINTEND(hicpp-signed-bitwise)
}

static void status_mgmt_event_handler(
    struct net_mgmt_event_callback *event_cb, uint64_t mgmt_event, struct net_if *iface)
{
    (void) event_cb;
    (void) iface;

    // NOLINTBEGIN(hicpp-signed-bitwise)
    switch (mgmt_event) {
        case NET_EVENT_IF_DOWN:
            LOG_DBG("Network event: NET_EVENT_IF_DOWN."); // NOLINT
            atomic_clear_bit(&eth_flags, IFACE_UP);
            break;

        case NET_EVENT_IF_UP:
            LOG_DBG("Network event: NET_EVENT_IF_UP."); // NOLINT
            atomic_set_bit(&eth_flags, IFACE_UP);
            break;

        case NET_EVENT_IF_ADMIN_DOWN:
            LOG_DBG("Network event: NET_EVENT_IF_ADMIN_DOWN."); // NOLINT
            break;

        case NET_EVENT_IF_ADMIN_UP:
            LOG_DBG("Network event: NET_EVENT_IF_ADMIN_UP."); // NOLINT
            break;

        default:
            LOG_DBG("Status network event: %lld.", mgmt_event); // NOLINT
            break;
    }
    // NOLINTEND(hicpp-signed-bitwise)
}

static void ipv6_mgmt_event_handler(
    struct net_mgmt_event_callback *event_cb, uint64_t mgmt_event, struct net_if *iface)
{
    (void) event_cb;
    (void) iface;

    // NOLINTBEGIN(hicpp-signed-bitwise)
    switch (mgmt_event) {

        case NET_EVENT_IPV6_ADDR_ADD:
            LOG_DBG("IPv6 network event: NET_EVENT_IPV6_ADDR_ADD."); // NOLINT
            break;

        case NET_EVENT_IPV6_ADDR_DEL:
            LOG_DBG("IPv6 network event: NET_EVENT_IPV6_ADDR_DEL."); // NOLINT
            break;

        case NET_EVENT_IPV6_MADDR_ADD:
            LOG_DBG("IPv6 network event: NET_EVENT_IPV6_MADDR_ADD."); // NOLINT
            break;

        case NET_EVENT_IPV6_MADDR_DEL:
            LOG_DBG("IPv6 network event: NET_EVENT_IPV6_MADDR_DEL."); // NOLINT
            break;

        case NET_EVENT_IPV6_PREFIX_ADD:
            LOG_DBG("IPv6 network event: NET_EVENT_IPV6_PREFIX_ADD."); // NOLINT
            break;

        case NET_EVENT_IPV6_PREFIX_DEL:
            LOG_DBG("IPv6 network event: NET_EVENT_IPV6_PREFIX_DEL."); // NOLINT
            break;

        case NET_EVENT_IPV6_MCAST_JOIN:
            LOG_DBG("IPv6 network event: NET_EVENT_IPV6_MCAST_JOIN."); // NOLINT
            break;

        case NET_EVENT_IPV6_MCAST_LEAVE:
            LOG_DBG("IPv6 network event: NET_EVENT_IPV6_MCAST_LEAVE."); // NOLINT
            break;

        case NET_EVENT_IPV6_ROUTER_ADD:
            LOG_DBG("IPv6 network event: NET_EVENT_IPV6_ROUTER_ADD."); // NOLINT
            break;

        case NET_EVENT_IPV6_ROUTER_DEL:
            LOG_DBG("IPv6 network event: NET_EVENT_IPV6_ROUTER_DEL."); // NOLINT
            break;

        case NET_EVENT_IPV6_ROUTE_ADD:
            LOG_DBG("IPv6 network event: NET_EVENT_IPV6_ROUTE_ADD."); // NOLINT
            break;

        case NET_EVENT_IPV6_ROUTE_DEL:
            LOG_DBG("IPv6 network event: NET_EVENT_IPV6_ROUTE_DEL."); // NOLINT
            break;

        case NET_EVENT_IPV6_DAD_SUCCEED:
            LOG_DBG("IPv6 network event: NET_EVENT_IPV6_DAD_SUCCEED."); // NOLINT
            break;

        case NET_EVENT_IPV6_DAD_FAILED:
            LOG_DBG("IPv6 network event: NET_EVENT_IPV6_DAD_FAILED."); // NOLINT
            break;

        case NET_EVENT_IPV6_NBR_ADD:
            LOG_DBG("IPv6 network event: NET_EVENT_IPV6_NBR_ADD."); // NOLINT
            break;

        case NET_EVENT_IPV6_NBR_DEL:
            LOG_DBG("IPv6 network event: NET_EVENT_IPV6_NBR_DEL."); // NOLINT
            break;

        case NET_EVENT_IPV6_DHCP_START:
            LOG_DBG("IPv6 network event: NET_EVENT_IPV6_DHCP_START."); // NOLINT
            break;

        case NET_EVENT_IPV6_DHCP_BOUND:
            LOG_DBG("IPv6 network event: NET_EVENT_IPV6_DHCP_BOUND."); // NOLINT
            break;

        case NET_EVENT_IPV6_DHCP_STOP:
            LOG_DBG("IPv6 network event: NET_EVENT_IPV6_DHCP_STOP."); // NOLINT
            break;

        default:
            LOG_DBG("IPv6 network event: %lld.", mgmt_event); // NOLINT
            break;
    }
    // NOLINTEND(hicpp-signed-bitwise)
}

static void ipv4_mgmt_event_handler(
    struct net_mgmt_event_callback *event_cb, uint64_t mgmt_event, struct net_if *iface)
{
    (void) event_cb;
    (void) iface;

    // NOLINTBEGIN(hicpp-signed-bitwise)
    switch (mgmt_event) {

        case NET_EVENT_IPV4_ADDR_ADD:
            LOG_DBG("Network event: NET_EVENT_IPV4_ADDR_ADD."); // NOLINT
            atomic_set_bit(&eth_flags, IPV4_ADDRESS_OBTAINED);
            break;

        case NET_EVENT_IPV4_ADDR_DEL:
            LOG_DBG("Network event: NET_EVENT_IPV4_ADDR_DEL."); // NOLINT
            atomic_clear_bit(&eth_flags, IPV4_ADDRESS_OBTAINED);
            break;

        case NET_EVENT_IPV4_MADDR_ADD:
            LOG_DBG("Network event: NET_EVENT_IPV4_MADDR_ADD."); // NOLINT
            break;

        case NET_EVENT_IPV4_MADDR_DEL:
            LOG_DBG("Network event: NET_EVENT_IPV4_MADDR_DEL."); // NOLINT
            break;

        case NET_EVENT_IPV4_ROUTER_ADD:
            LOG_DBG("Network event: NET_EVENT_IPV4_ROUTER_ADD."); // NOLINT
            break;

        case NET_EVENT_IPV4_ROUTER_DEL:
            LOG_DBG("Network event: NET_EVENT_IPV4_ROUTER_DEL."); // NOLINT
            break;

        case NET_EVENT_IPV4_DHCP_START:
            LOG_DBG("Network event: NET_EVENT_IPV4_DHCP_START."); // NOLINT
            break;

        case NET_EVENT_IPV4_DHCP_BOUND:
            LOG_DBG("Network event: NET_EVENT_IPV4_DHCP_BOUND."); // NOLINT
            break;

        case NET_EVENT_IPV4_DHCP_STOP:
            LOG_DBG("Network event: NET_EVENT_IPV4_DHCP_STOP."); // NOLINT
            break;

        case NET_EVENT_IPV4_MCAST_JOIN:
            LOG_DBG("Network event: NET_EVENT_IPV4_MCAST_JOIN."); // NOLINT
            break;

        case NET_EVENT_IPV4_MCAST_LEAVE:
            LOG_DBG("Network event: NET_EVENT_IPV4_MCAST_LEAVE."); // NOLINT
            break;

        default:
            LOG_DBG("Network event: %lld.", mgmt_event); // NOLINT
            break;
    }
    // NOLINTEND(hicpp-signed-bitwise)
}

static void l4_mgmt_event_handler(
    struct net_mgmt_event_callback *event_cb, uint64_t mgmt_event, struct net_if *iface)
{
    (void) event_cb;
    (void) iface;

    // NOLINTBEGIN(hicpp-signed-bitwise)
    switch (mgmt_event) {

        case NET_EVENT_L4_CONNECTED:
            LOG_DBG("Network event: NET_EVENT_L4_CONNECTED."); // NOLINT
            break;

        case NET_EVENT_L4_DISCONNECTED:
            LOG_DBG("Network event: NET_EVENT_L4_DISCONNECTED."); // NOLINT
            break;

        case NET_EVENT_DNS_SERVER_ADD:
            LOG_DBG("Network event: NET_EVENT_DNS_SERVER_ADD."); // NOLINT
            break;

        case NET_EVENT_DNS_SERVER_DEL:
            LOG_DBG("Network event: NET_EVENT_DNS_SERVER_DEL."); // NOLINT
            break;

        case NET_EVENT_HOSTNAME_CHANGED:
            LOG_DBG("Network event: NET_EVENT_HOSTNAME_CHANGED."); // NOLINT
            break;

        default:
            LOG_DBG("Network event: %lld.", mgmt_event); // NOLINT
            break;
    }
    // NOLINTEND(hicpp-signed-bitwise)
}

/************************************************
 *         Global functions definition          *
 ***********************************************/

int eth_connect(void)
{
    LOG_INF("Connecting through ethernet..."); // NOLINT

    // NOLINTBEGIN(hicpp-signed-bitwise, misc-redundant-expression)
    net_mgmt_init_event_callback(&eth_cb, eth_mgmt_event_handler,
        NET_EVENT_ETHERNET_CARRIER_ON | NET_EVENT_ETHERNET_CARRIER_OFF
            | NET_EVENT_ETHERNET_VLAN_TAG_ENABLED | NET_EVENT_ETHERNET_VLAN_TAG_DISABLED);
    net_mgmt_init_event_callback(&status_cb, status_mgmt_event_handler,
        NET_EVENT_IF_DOWN | NET_EVENT_IF_UP | NET_EVENT_IF_ADMIN_DOWN | NET_EVENT_IF_ADMIN_UP);
    net_mgmt_init_event_callback(&ipv6_cb, ipv6_mgmt_event_handler,
        NET_EVENT_IPV6_ADDR_ADD | NET_EVENT_IPV6_ADDR_DEL | NET_EVENT_IPV6_MADDR_ADD
            | NET_EVENT_IPV6_MADDR_DEL | NET_EVENT_IPV6_PREFIX_ADD | NET_EVENT_IPV6_PREFIX_DEL
            | NET_EVENT_IPV6_MCAST_JOIN | NET_EVENT_IPV6_MCAST_LEAVE | NET_EVENT_IPV6_ROUTER_ADD
            | NET_EVENT_IPV6_ROUTER_DEL | NET_EVENT_IPV6_ROUTE_ADD | NET_EVENT_IPV6_ROUTE_DEL
            | NET_EVENT_IPV6_DAD_SUCCEED | NET_EVENT_IPV6_DAD_FAILED | NET_EVENT_IPV6_NBR_ADD
            | NET_EVENT_IPV6_NBR_DEL | NET_EVENT_IPV6_DHCP_START | NET_EVENT_IPV6_DHCP_BOUND
            | NET_EVENT_IPV6_DHCP_STOP);
    net_mgmt_init_event_callback(&ipv4_cb, ipv4_mgmt_event_handler,
        NET_EVENT_IPV4_ADDR_ADD | NET_EVENT_IPV4_ADDR_DEL | NET_EVENT_IPV4_MADDR_ADD
            | NET_EVENT_IPV4_MADDR_DEL | NET_EVENT_IPV4_ROUTER_ADD | NET_EVENT_IPV4_ROUTER_DEL
            | NET_EVENT_IPV4_DHCP_START | NET_EVENT_IPV4_DHCP_BOUND | NET_EVENT_IPV4_DHCP_STOP
            | NET_EVENT_IPV4_MCAST_JOIN | NET_EVENT_IPV4_MCAST_LEAVE);
    net_mgmt_init_event_callback(&l4_cb, l4_mgmt_event_handler,
        NET_EVENT_L4_CONNECTED | NET_EVENT_L4_DISCONNECTED | NET_EVENT_DNS_SERVER_ADD
            | NET_EVENT_DNS_SERVER_DEL | NET_EVENT_HOSTNAME_CHANGED);
    // NOLINTEND(hicpp-signed-bitwise, misc-redundant-expression)

    net_mgmt_add_event_callback(&eth_cb);
    net_mgmt_add_event_callback(&status_cb);
    net_mgmt_add_event_callback(&ipv6_cb);
    net_mgmt_add_event_callback(&ipv4_cb);
    net_mgmt_add_event_callback(&l4_cb);

    // Guaranteed to be Ethernet, not Loopback or Wi-Fi
    struct net_if *iface = net_if_get_first_by_type(&NET_L2_GET_NAME(ETHERNET));
    if (!iface) {
        LOG_ERR("Ethernet interface non existant."); // NOLINT
        return -1;
    }

    const struct device *dev = net_if_get_device(iface);
    LOG_INF("Ethernet network interface device name: %s.", dev->name); // NOLINT
    struct ethernet_context *eth_ctx = net_if_l2_data(iface);
    LOG_INF("Ethernet carrier: %s.", eth_ctx->is_net_carrier_up ? "UP" : "DOWN"); // NOLINT
    LOG_INF("Ethernet context is initialized: %s.", eth_ctx->is_init ? "YES" : "NO"); // NOLINT
    enum net_if_oper_state iface_oper_state = net_if_oper_state(iface);
    LOG_INF("Ethernet network interface operational state: %d.", iface_oper_state); // NOLINT

    if (iface_oper_state != NET_IF_OPER_UP) {
        LOG_INF("Waiting for Ethernet interface to be operational..."); // NOLINT
        while (!atomic_test_bit(&eth_flags, IFACE_UP)) {
            k_sleep(K_MSEC(200));
        }
    }

#ifdef CONFIG_NET_DHCPV4
    net_dhcpv4_start(iface);

    LOG_INF("Waiting for an IPv4 address (DHCP)."); // NOLINT
    while (!atomic_test_bit(&eth_flags, IPV4_ADDRESS_OBTAINED)) {
        k_sleep(K_MSEC(200));
    }
#endif

    LOG_INF("Ready..."); // NOLINT

    return 0;
}

int eth_poll(void)
{
    struct net_if *iface = net_if_get_first_by_type(&NET_L2_GET_NAME(ETHERNET));
    if (!iface) {
        LOG_ERR("Ethernet interface non existant."); // NOLINT
        return -1;
    }

    // Check if connected, warn once to prevent spam
    bool warned = false;
    while (net_if_oper_state(iface) != NET_IF_OPER_UP) {
        if (!warned) {
            LOG_WRN("Ethernet interface is non operational. Waiting..."); // NOLINT
            warned = true;
        }
        k_sleep(K_MSEC(200));
    }

// Restart DHCP if required.
#ifdef CONFIG_NET_DHCPV4
    if (!atomic_test_bit(&eth_flags, IPV4_ADDRESS_OBTAINED)) {
        LOG_WRN("Missing IPv4 address."); // NOLINT
        net_dhcpv4_restart(iface);

        LOG_INF("Waiting for an IPv4 address (DHCP)."); // NOLINT
        while (!atomic_test_bit(&eth_flags, IPV4_ADDRESS_OBTAINED)) {
            k_sleep(K_MSEC(200));
        }
        LOG_INF("Ready..."); // NOLINT
    }
#endif

    return 0;
}
```
